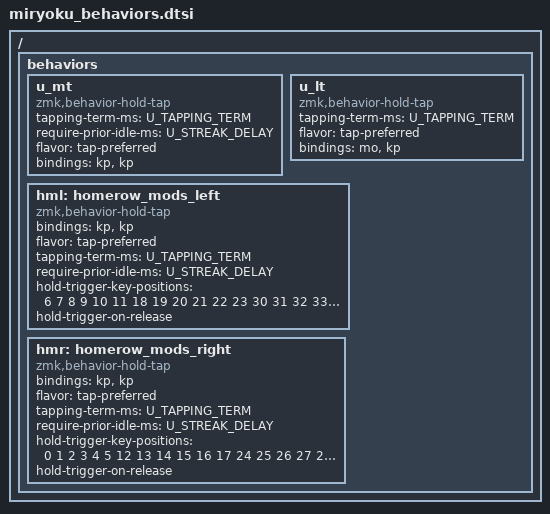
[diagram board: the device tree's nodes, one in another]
// Copyright 2022 Manna Harbour
// https://github.com/manna-harbour/miryoku

/ {
  behaviors {
    u_mt: u_mt {
      compatible = "zmk,behavior-hold-tap";
      #binding-cells = <2>;
      tapping-term-ms = <U_TAPPING_TERM>;
      require-prior-idle-ms = <U_STREAK_DELAY>;
      flavor = "tap-preferred";
      bindings = <&kp>, <&kp>;
    };
    u_lt: u_lt {
      compatible = "zmk,behavior-hold-tap";
      #binding-cells = <2>;
      tapping-term-ms = <U_TAPPING_TERM>;
      flavor = "tap-preferred";
      bindings = <&mo>, <&kp>;
    };

    // Home row mod behaviors based on sunaku's implementation
    hml: homerow_mods_left {
      compatible = "zmk,behavior-hold-tap";
      #binding-cells = <2>;
      bindings = <&kp>, <&kp>;
      flavor = "tap-preferred";
      tapping-term-ms = <U_TAPPING_TERM>;
      require-prior-idle-ms = <U_STREAK_DELAY>;
      hold-trigger-key-positions = <6 7 8 9 10 11 18 19 20 21 22 23 30 31 32 33 34 35 36 37 38 39 40 41>; // right hand + thumbs
      hold-trigger-on-release;
    };

    hmr: homerow_mods_right {
      compatible = "zmk,behavior-hold-tap";
      #binding-cells = <2>;
      bindings = <&kp>, <&kp>;
      flavor = "tap-preferred";
      tapping-term-ms = <U_TAPPING_TERM>;
      require-prior-idle-ms = <U_STREAK_DELAY>;
      hold-trigger-key-positions = <0 1 2 3 4 5 12 13 14 15 16 17 24 25 26 27 28 29 36 37 38 39 40 41>; // left hand + thumbs
      hold-trigger-on-release;
    };
  };
};
